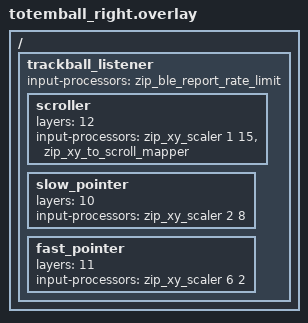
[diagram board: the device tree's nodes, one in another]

#include <input/processors/report_rate_limit.dtsi>

/ {
    trackball_listener {
        input-processors = <&zip_ble_report_rate_limit>;

        scroller: scroller {
            layers           = <12>;
            input-processors = <
                &zip_xy_scaler 1 15           // Scales the scroll speed
                &zip_xy_to_scroll_mapper      // Converts XY movement to scroll events
            >;
        };
        slow_pointer: slow_pointer {
            layers           = <10>;
            input-processors = <&zip_xy_scaler 2 8>;
        };
        fast_pointer: fast_pointer {
            layers           = <11>;
            input-processors = <&zip_xy_scaler 6 2>;
        };
    };
};
